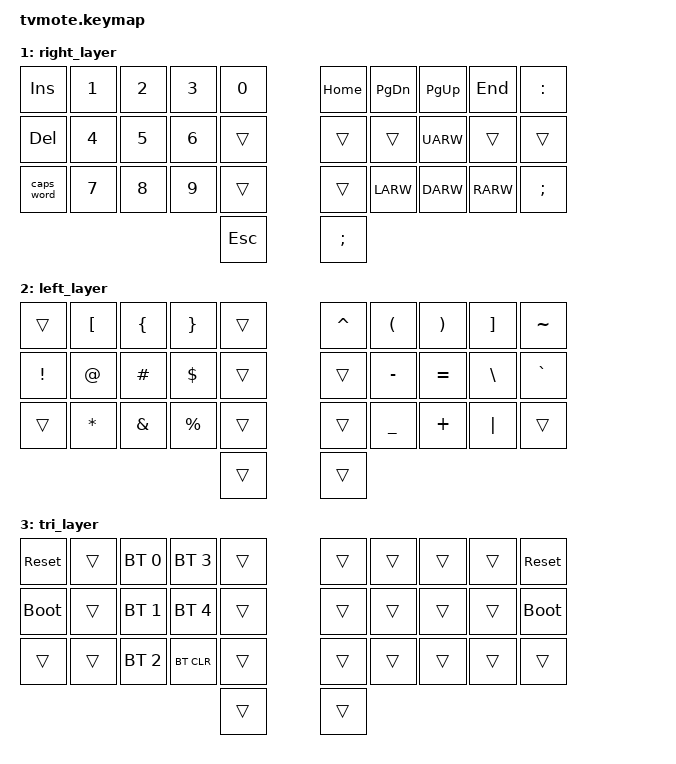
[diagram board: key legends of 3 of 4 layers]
#include <behaviors.dtsi>
#include <dt-bindings/zmk/keys.h>
#include <dt-bindings/zmk/bt.h>

// Home row mods macro
#define HRML(k1,k2,k3,k4) &ht LSHFT k1  &ht LALT k2  &ht LCTRL k3  &ht LGUI k4
#define HRMR(k1,k2,k3,k4) &ht RGUI k1  &ht RCTRL k2  &ht RALT k3  &ht RSHFT k4

/ {
    behaviors {
        ht: hold_tap {
            compatible = "zmk,behavior-hold-tap";
            #binding-cells = <2>;
            flavor = "tap-preferred";
            tapping-term-ms = <220>;
            quick-tap-ms = <150>;
            require-prior-idle-ms = <100>;
            bindings = <&kp>, <&kp>;
        };
    };

    conditional_layers {
        compatible = "zmk,conditional-layers";
        tri_layer {
            if-layers = <1 2>;
            then-layer = <3>;
        };
    };

    combos {
        compatible = "zmk,combos";
        combo_lr_1 {
            timeout-ms = <50>;
            key-positions = <14 24>;
            bindings = <&lt 1 ESC>;
        };
        
        combo_lr_2 {
            timeout-ms = <50>;
            key-positions = <15 25>;
            bindings = <&lt 2 BSPC>;
        };
    };

    keymap {
        compatible = "zmk,keymap";
        default_layer {
            bindings = <
        //╭──────────┬──────────┬──────────┬──────────┬──────────╮   ╭──────────┬──────────┬──────────┬──────────┬──────────╮
        //│  Q       │  W       │  E       │  R       │  T       │   │  Y       │  U       │  I       │  O       │  P       │
            &kp Q      &kp W      &kp E      &kp R      &kp T         &kp Y       &kp U      &kp I      &kp O      &ht BSPC P
        //├──────────┼──────────┼──────────┼──────────┼──────────┤   ├──────────┼──────────┼──────────┼──────────┼──────────┤
        //│  A       │  S       │  D       │  F       │  G       │   │  H       │  J       │  K       │  L       │ ' "      │
            HRML(A,        S,         D,         F)     &kp G          &kp H      HRMR(J,        K,         L,        SQT)
        //├──────────┼──────────┼──────────┼──────────┼──────────┤   ├──────────┼──────────┼──────────┼──────────┼──────────┤
        //│  Z       │  X       │  C       │  V       │  B       │   │  N       │  M       │ , <      │ . >      │ / ?      │
            &kp Z      &kp X      &kp C      &kp V      &kp B          &kp N      &kp M      &kp COMMA  &kp DOT    &kp FSLH
        //╰──────────┴──────────┴──────────┼──────────┼──────────┤   ├──────────┼──────────┼──────────┴──────────┴──────────╯
                                                        &kp ENTER     &kp SPACE 
        //                                            ╰──────────╯   ╰──────────╯
            >;
        };

        right_layer {
            bindings = <
        //╭──────────┬──────────┬──────────┬──────────┬──────────╮   ╭──────────┬──────────┬──────────┬──────────┬──────────╮
        //│ INSERT   │  1       │  2       │  3       │  0       │   │ HOME     │ PAGE DN  │ PAGE UP  │ END      │  :       │
            &kp INS    &kp N1     &kp N2     &kp N3     &kp N0         &kp HOME   &kp PG_DN  &kp PG_UP  &kp END    &kp COLON
        //├──────────┼──────────┼──────────┼──────────┼──────────┤   ├──────────┼──────────┼──────────┼──────────┼──────────┤
        //│ DELETE   │  4       │  5       │  6       │          │   │                     │ UP       │          │
            &kp DEL    &kp N4     &kp N5     &kp N6     &trans         &trans     &trans     &kp UARW   &trans     &trans
        //├──────────┼──────────┼──────────┼──────────┼──────────┤   ├──────────┼──────────┼──────────┼──────────┼──────────┤
        //│ CAPS     │  7       │  8       │  9       │          │   │          │ LEFT     │ DOWN     │ RIGHT    │  ;       │
           &caps_word  &kp N7     &kp N8     &kp N9     &trans         &trans     &kp LARW   &kp DARW   &kp RARW   &kp SEMI
        //╰──────────┴──────────┴──────────┼──────────┼──────────┤   ├──────────┼──────────┼──────────┴──────────┴──────────╯
                                                        &kp ESC        &kp SEMI   
        //                                            ╰──────────╯   ╰──────────╯
            >;
        };

        left_layer {
            bindings = <
        //╭──────────┬──────────┬──────────┬──────────┬──────────╮   ╭──────────┬──────────┬──────────┬──────────┬──────────╮
        //│          │  [       │  {       │  }       │          │   │  ^       │  (       │  )       │  ]       │  ~       │
            &trans     &kp LBKT   &kp LBRC   &kp RBRC   &trans         &kp CARET  &kp LPAR   &kp RPAR   &kp RBKT   &kp TILDE
        //├──────────┼──────────┼──────────┼──────────┼──────────┤   ├──────────┼──────────┼──────────┼──────────┼──────────┤
        //│  !       │  @       │  #       │  $       │          │   │          │  -       │  =       │  \       │  `       │
            &kp EXCL   &kp AT     &kp HASH   &kp DLLR   &trans         &trans     &kp MINUS  &kp EQUAL  &kp BSLH   &kp GRAVE
        //├──────────┼──────────┼──────────┼──────────┼──────────┤   ├──────────┼──────────┼──────────┼──────────┼──────────┤
        //│          │  *       │  &       │  %       │          │   │          │  _       │  +       │  │       │          │
            &trans     &kp ASTRK  &kp AMPS   &kp PRCNT  &trans         &trans     &kp UNDER  &kp PLUS   &kp PIPE   &trans
        //╰──────────┴──────────┴──────────┼──────────┼──────────┤   ├──────────┼──────────┼──────────┴──────────┴──────────╯
                                                        &trans         &trans    
        //                                            ╰──────────╯   ╰──────────╯
            >;
        };

        tri_layer {
            bindings = <
        //╭──────────┬──────────┬──────────┬──────────┬──────────╮   ╭──────────┬──────────┬──────────┬──────────┬──────────╮
        //│ RESET    │          │PROFILE 0 │          │          │   │          │          │          │          │  RESET   │
           &sys_reset  &trans    &bt BT_SEL 0   &bt BT_SEL 3    &trans         &trans     &trans     &trans     &trans    &sys_reset
        //├──────────┼──────────┼──────────┼──────────┼──────────┤   ├──────────┼──────────┼──────────┼──────────┼──────────┤
        //│BOOTLOADER│          │PROFILE 1 │          │          │   │          │          │          │          │BOOTLOADER│
          &bootloader  &trans    &bt BT_SEL 1   &bt BT_SEL 4    &trans         &trans     &trans     &trans     &trans    &bootloader
        //├──────────┼──────────┼──────────┼──────────┼──────────┤   ├──────────┼──────────┼──────────┼──────────┼──────────┤
        //│          │          │PROFILE 2 │ CLEAR BT │          │   │          │          │          │          │          │
            &trans     &trans    &bt BT_SEL 2 &bt BT_CLR &trans        &trans     &trans     &trans     &trans     &trans
        //╰──────────┴──────────┴──────────┼──────────┼──────────┤   ├──────────┼──────────┼──────────┴──────────┴──────────╯
                                                        &trans         &trans
        //                                            ╰──────────╯   ╰──────────╯
            >;
        };
    };
};
